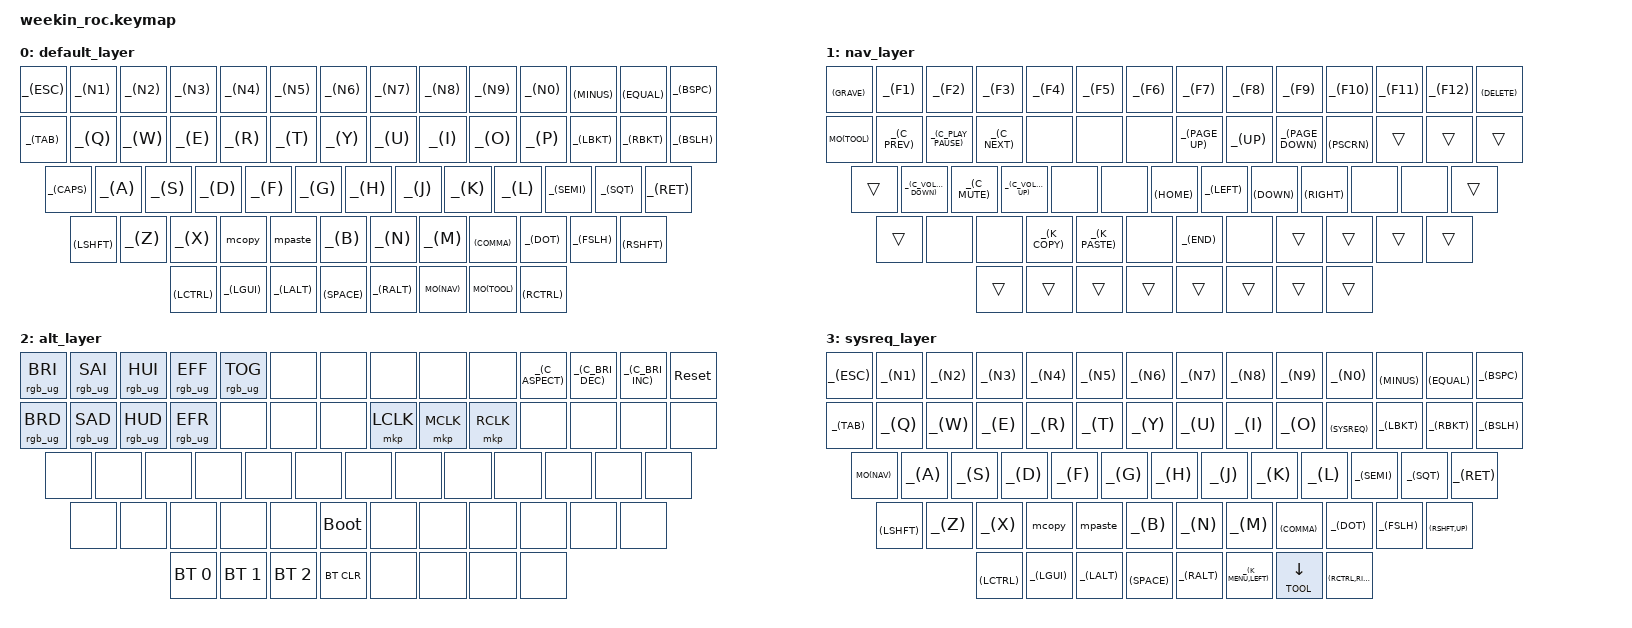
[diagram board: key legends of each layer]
/*
 * Copyright (c) 2020 The ZMK Contributors
 *
 * SPDX-License-Identifier: MIT
 */

#include <behaviors.dtsi>
#include <dt-bindings/zmk/keys.h>
#include <dt-bindings/zmk/mouse.h>
#include <dt-bindings/zmk/ext_power.h>
#include <dt-bindings/zmk/bt.h>
#include <dt-bindings/zmk/rgb.h>

#define none &none
#define ____ &trans

#define BASE  0
#define NAV   1
#define TOOL  2
#define SYSRQ 3

// Default key macro
#define _(KEY) &kp KEY
// Key tap macro
#define __(KEY, TAP) &mt KEY TAP
// Layer macro
#define MO(LAYER) &mo LAYER
// Define Mouse button
#define M_LCLK &mkp LCLK
#define M_RCLK &mkp RCLK
#define M_MCLK &mkp MCLK

/ {

  behaviors {
    mcopy: mod_copy {
      compatible = "zmk,behavior-mod-morph";
      label = "MOD_COPY";
      #binding-cells = <0>;
      bindings = <&kp C>, <&kp C_AC_COPY>;
      mods = <(MOD_LGUI|MOD_RGUI)>;
    };

    mpaste: mod_paste {
      compatible = "zmk,behavior-mod-morph";
      label = "MOD_PASTE";
      #binding-cells = <0>;
      bindings = <&kp V>, <&kp K_PASTE>;
      mods = <(MOD_LGUI|MOD_RGUI)>;
    };

    lmt: layer_mod_tap {
      compatible = "zmk,behavior-hold-tap";
      label = "LAYER_MOD_TAP";
      #binding-cells = <2>;
      flavor = "hold-preferred";
      tapping-term-ms = <200>;
      bindings = <&mo>, <&kp>;
    };
  };

  keymap0: keymap {
    compatible = "zmk,keymap";

    // # layer 0 - default
    // ╭─────┬─────┬─────┬─────┬─────┬─────┬─────┬─────┬─────┬─────┬─────┬─────┬─────┬─────────╮
    // | ESC |  1  |  2  |  3  |  4  |  5  |  6  |  7  |  8  |  9  |  0  |  -  |  =  |   ⌫    |
    // |─────┴─┬───┴─┬───┴─┬───┴─┬───┴─┬───┴─┬───┴─┬───┴─┬───┴─┬───┴─┬───┴─┬───┴─┬───┴─┬───────|
    // |  ─>|  |  Q  |  W  |  E  |  R  |  T  |  Y  |  U  |  I  |  O  |  P  |  [  |  ]  |   \   |
    // |───────┴┬────┴┬────┴┬────┴┬────┴┬────┴┬────┴┬────┴┬────┴┬────┴┬────┴┬────┴┬────┴───────|
    // |  NAV   |  A  |  S  |  D  |  F  |  G  |  H  |  J  |  K  |  L  |  ;  |  '  |     ↵     |
    // |────────┴─┬───┴─┬───┴─┬───┴─┬───┴─┬───┴─┬───┴─┬───┴─┬───┴─┬───┴─┬───┴─┬───┴────────────|
    // |    ⇧     |  Z  |  X  |  C  |  V  |  B  |  N  |  M  |  ,  |  .  |  /  |       ⇧        |
    // |──────┬───┴──┬──┴──┬──┴─────┴─────┴─────┴─────┴─────┴───┬─┴─────┼─────┴┬──────┬────────|
    // | Ctrl | Win  | Alt |                                    |  Alt  | Menu | TOOL |  Ctrl  |
    // ╰──────┴──────┴─────┴────────────────────────────────────┴───────┴──────┴──────┴────────╯

    default_layer {
      bindings = <
        _(ESC) _(N1)  _(N2)  _(N3)  _(N4)  _(N5)  _(N6)  _(N7)  _(N8)  _(N9)  _(N0)  _(MINUS) _(EQUAL) _(BSPC)
        _(TAB)  _(Q)   _(W)   _(E)   _(R)   _(T)   _(Y)   _(U)   _(I)   _(O)   _(P)  _(LBKT)  _(RBKT)  _(BSLH)
        _(CAPS) _(A)   _(S)   _(D)   _(F)   _(G)   _(H)   _(J)   _(K)   _(L)  _(SEMI) _(SQT)       _(RET)
        _(LSHFT)  _(Z)   _(X)   &mcopy   &mpaste   _(B)   _(N)   _(M)  _(COMMA) _(DOT)  _(FSLH)       _(RSHFT)
        _(LCTRL) _(LGUI) _(LALT)               _(SPACE)           _(RALT)  MO(NAV)  MO(TOOL)   _(RCTRL)
      >;
    };

    // # layer 1 - navigation
    // ╭─────┬─────┬─────┬─────┬─────┬─────┬─────┬─────┬─────┬─────┬─────┬─────┬─────┬─────────╮
    // |  `  | F1  | F2  | F3  | F4  | F5  | F6  | F7  | F8  | F9  | F10 | F11 | F12 |   ⌦    |
    // |─────┴─┬───┴─┬───┴─┬───┴─┬───┴─┬───┴─┬───┴─┬───┴─┬───┴─┬───┴─┬───┴─┬───┴─┬───┴─┬───────|
    // | TOOL  | ⏮  | ⏯  | ⏭  |     |     |     |  ⇞  |  ↑  |  ⇟  |PRINT|     |     |       |
    // |───────┴┬────┴┬────┴┬────┴┬────┴┬────┴┬────┴┬────┴┬────┴┬────┴┬────┴┬────┴┬────┴───────|
    // |        |  🕩 | 🔇 | 🕪  |     |     | ⇤  | ←  |  ↓  |  → |     |     |     ↵     |
    // |────────┴─┬───┴─┬───┴─┬───┴─┬───┴─┬───┴─┬───┴─┬───┴─┬───┴─┬───┴─┬───┴─┬───┴────────────|
    // |     ⇧    |     |     |COPY |PASTE|     |  ⇥ |     |     |     |     |       ⇧        |
    // |──────┬───┴──┬──┴──┬──┴─────┴─────┴─────┴─────┴─────┴───┬─┴─────┼─────┴┬──────┬────────|
    // | Ctrl | Win  | alt |                                    |  alt  | Menu | TOOL |  Ctrl  |
    // ╰──────┴──────┴─────┴────────────────────────────────────┴───────┴──────┴──────┴────────╯

    nav_layer {
      bindings = <
_(GRAVE)  _(F1)  _(F2)  _(F3)  _(F4)  _(F5)  _(F6)  _(F7)  _(F8)  _(F9)  _(F10)  _(F11)  _(F12) _(DELETE)
MO(TOOL)     _(C_PREV) _(C_PLAY_PAUSE) _(C_NEXT)  none  none  none  _(PAGE_UP)  _(UP)  _(PAGE_DOWN)  _(PSCRN)  ____  ____  ____
____     _(C_VOLUME_DOWN)  _(C_MUTE) _(C_VOLUME_UP) none none  _(HOME) _(LEFT) _(DOWN)   _(RIGHT)  none   none  ____
____     none      none      _(K_COPY)      _(K_PASTE)      none      _(END)      none      ____      ____      ____      ____
____       ____       ____       ____                                              ____     ____     ____     ____
      >;
    };

    // # layer 2 - Tools and bootloader
    // ╭─────┬─────┬─────┬─────┬─────┬─────┬─────┬─────┬─────┬─────┬─────┬─────┬─────┬─────────╮
    // | BRI+| SAT+| HUE+| ANI+| TOG |     |     |     |     |     |  🖵 | 🔅 |  🔆 |  RESET  |
    // |─────┴─┬───┴─┬───┴─┬───┴─┬───┴─┬───┴─┬───┴─┬───┴─┬───┴─┬───┴─┬───┴─┬───┴─┬───┴─┬───────|
    // | BRI-  | SAT-| HUE-| ANI-|     |     |     |  ‹ | 🖱️↑ |  ›  |     |     |     |       |
    // |───────┴┬────┴┬────┴┬────┴┬────┴┬────┴┬────┴┬────┴┬────┴┬────┴┬────┴┬────┴┬────┴───────|
    // |        |     |     |     |     |  ↟  |🖱️←| 🖱️↓ |🖱️→|     |     |            |
    // |────────┴─┬───┴─┬───┴─┬───┴─┬───┴─┬───┴─┬───┴─┬───┴─┬───┴─┬───┴─┬───┴─┬───┴────────────|
    // |          |     |     |     |     | 🥾  |  ↡  |     |     |     |     |                |
    // |──────┬───┴──┬──┴──┬──┴─────┴─────┴─────┴─────┴─────┴───┬─┴─────┼─────┴┬──────┬────────|
    // |      |      |     |                                    |       |      |      |        |
    // ╰──────┴──────┴─────┴────────────────────────────────────┴───────┴──────┴──────┴────────╯

    alt_layer {
      bindings = <
&rgb_ug RGB_BRI &rgb_ug RGB_SAI  &rgb_ug RGB_HUI &rgb_ug RGB_EFF &rgb_ug RGB_TOG none none none none none _(C_ASPECT) _(C_BRI_DEC) _(C_BRI_INC) &sys_reset
&rgb_ug RGB_BRD &rgb_ug RGB_SAD  &rgb_ug RGB_HUD &rgb_ug RGB_EFR none none none M_LCLK M_MCLK M_RCLK none none none none
none none none none none none none none none none none none none
none none none none none &bootloader none none none none none none
&bt BT_SEL 0 &bt BT_SEL 1 &bt BT_SEL 2             &bt BT_CLR              none none none none
      >;
    };

    // # layer 3 - SYSREQ
    // ╭─────┬─────┬─────┬─────┬─────┬─────┬─────┬─────┬─────┬─────┬─────┬─────┬─────┬─────────╮
    // | ESC |  1  |  2  |  3  |  4  |  5  |  6  |  7  |  8  |  9  |  0  |  -  |  =  |   ⌫    |
    // |─────┴─┬───┴─┬───┴─┬───┴─┬───┴─┬───┴─┬───┴─┬───┴─┬───┴─┬───┴─┬───┴─┬───┴─┬───┴─┬───────|
    // |  ─>|  |  Q  |  W  |  E  |  R  |  T  |  Y  |  U  |  I  |  O  |SYSRQ|  [  |  ]  |   \   |
    // |───────┴┬────┴┬────┴┬────┴┬────┴┬────┴┬────┴┬────┴┬────┴┬────┴┬────┴┬────┴┬────┴───────|
    // |  NAV   |  A  |  S  |  D  |  F  |  G  |  H  |  J  |  K  |  L  |  ;  |  '  |     ↵     |
    // |────────┴─┬───┴─┬───┴─┬───┴─┬───┴─┬───┴─┬───┴─┬───┴─┬───┴─┬───┴─┬───┴─┬───┴────────────|
    // |    ⇧     |  Z  |  X  |  C  |  V  |  B  |  N  |  M  |  ,  |  .  |  /  |       ⇧        |
    // |──────┬───┴──┬──┴──┬──┴─────┴─────┴─────┴─────┴─────┴───┬─┴─────┼─────┴┬──────┬────────|
    // | Ctrl | Win  | alt |                                    |  alt  | MENU | TOOL |  Ctrl  |
    // ╰──────┴──────┴─────┴────────────────────────────────────┴───────┴──────┴──────┴────────╯

    sysreq_layer {
      bindings = <
        _(ESC) _(N1)  _(N2)  _(N3)  _(N4)  _(N5)  _(N6)  _(N7)  _(N8)  _(N9)  _(N0)  _(MINUS) _(EQUAL) _(BSPC)
        _(TAB)  _(Q)   _(W)   _(E)   _(R)   _(T)   _(Y)   _(U)   _(I)   _(O)  _(SYSREQ) _(LBKT)  _(RBKT)  _(BSLH)
        MO(NAV) _(A)   _(S)   _(D)   _(F)   _(G)   _(H)   _(J)   _(K)   _(L)  _(SEMI) _(SQT)       _(RET)
        _(LSHFT)  _(Z)   _(X)   &mcopy   &mpaste   _(B)   _(N)   _(M)  _(COMMA) _(DOT)  _(FSLH)       __(RSHFT,UP)
        _(LCTRL) _(LGUI) _(LALT)               _(SPACE)           _(RALT)  __(K_MENU,LEFT)  &lmt TOOL DOWN   __(RCTRL,RIGHT)
      >;
    };
  };
};

&led_strip {
    chain-length = <10>;
};
